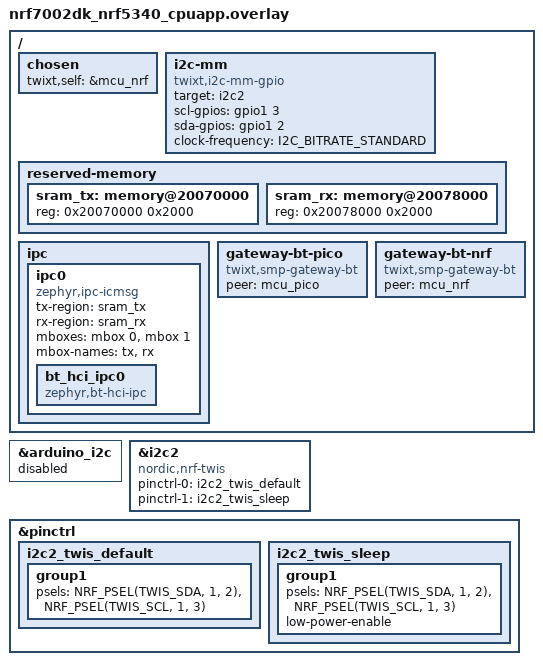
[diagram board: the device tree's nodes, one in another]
/*
 * Copyright (c) 2026 Christoph Jans <jans.christoph@gmail.com>
 *
 * SPDX-License-Identifier: Apache-2.0
 */

/* The bus on the Arduino SDA P1.02, SCL P1.03, at 1.8 V: TWIS2 is the target, the controller
 * software on the same pins (twixt,i2c-mm-gpio), as the TWIM cannot detect lost arbitration.
 */

#include <zephyr/dt-bindings/i2c/i2c.h>

/ {
	chosen {
		twixt,self = &mcu_nrf;
	};

	i2c-mm {
		compatible = "twixt,i2c-mm-gpio";
		target = <&i2c2>;
		scl-gpios = <&gpio1 3 0>;
		sda-gpios = <&gpio1 2 0>;
		clock-frequency = <I2C_BITRATE_STANDARD>;
		#address-cells = <1>;
		#size-cells = <0>;

#include "../twixt_mcus.dtsi"
	};
};

&arduino_i2c {
	status = "disabled";
};

&i2c2 {
	compatible = "nordic,nrf-twis";
	status = "okay";
	pinctrl-0 = <&i2c2_twis_default>;
	pinctrl-1 = <&i2c2_twis_sleep>;
	pinctrl-names = "default", "sleep";
};

&pinctrl {
	i2c2_twis_default: i2c2_twis_default {
		group1 {
			psels = <NRF_PSEL(TWIS_SDA, 1, 2)>,
				<NRF_PSEL(TWIS_SCL, 1, 3)>;
		};
	};

	i2c2_twis_sleep: i2c2_twis_sleep {
		group1 {
			psels = <NRF_PSEL(TWIS_SDA, 1, 2)>,
				<NRF_PSEL(TWIS_SCL, 1, 3)>;
			low-power-enable;
		};
	};
};


/* nrf, the gateway: a Bluetooth device for each MCU, itself included. The cores talk over icmsg, in
 * Zephyr itself, instead of the board's default that needs the open-amp module; hci_ipc.overlay is
 * the other side.
 */
/delete-node/ &sram0_shared;

/ {
	chosen {
		/delete-property/ zephyr,ipc_shm;
	};

	reserved-memory {
		#address-cells = <1>;
		#size-cells = <1>;

		sram_tx: memory@20070000 {
			reg = <0x20070000 0x2000>;
		};

		sram_rx: memory@20078000 {
			reg = <0x20078000 0x2000>;
		};
	};

	ipc {
		/delete-node/ ipc0;

		ipc0: ipc0 {
			compatible = "zephyr,ipc-icmsg";
			tx-region = <&sram_tx>;
			rx-region = <&sram_rx>;
			mboxes = <&mbox 0>, <&mbox 1>;
			mbox-names = "tx", "rx";
			status = "okay";

			bt_hci_ipc0: bt_hci_ipc0 {
				compatible = "zephyr,bt-hci-ipc";
				status = "okay";
			};
		};
	};

	gateway-bt-pico {
		compatible = "twixt,smp-gateway-bt";
		peer = <&mcu_pico>;
	};

	gateway-bt-nrf {
		compatible = "twixt,smp-gateway-bt";
		peer = <&mcu_nrf>;
	};
};
